# GD32H7xx register map
File version: 1.0
CPU: CM7 r1p2, little endian, MPU, FPU, 4 interrupt priority bits
Registers are 32-bit, read-write, reset 0x0 unless marked. A register's access mark holds for its fields unless they carry their own. Offsets are from the block's base; [hi:lo] are bit positions; {n}, {i} and the like mark numbered series.

## HWSEM — Hardware semaphore
Base 0x58026400
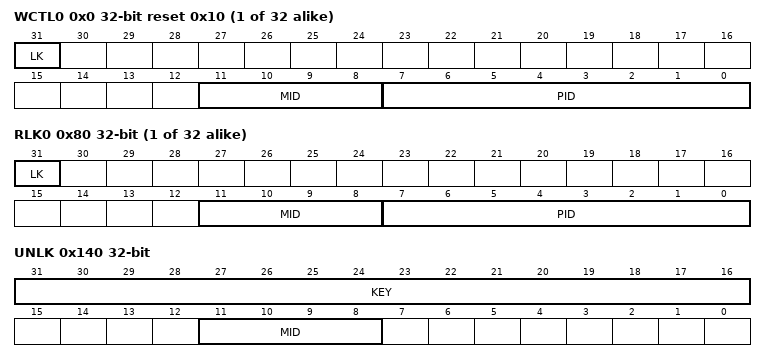
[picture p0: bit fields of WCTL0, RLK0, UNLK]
{0x0+4i} WCTL{i} reset 0x10 (i=0..31) — Write control register {i}
  [31] LK — Lock semaphore by writing
  [11:8] MID — Bus master identification
  [7:0] PID — Process identification
{0x80+4i} RLK{i} ro (i=0..31) — Read lock regist {i}
  [31] LK — Lock semaphore by reading
  [11:8] MID — Bus master identification
  [7:0] PID — Process identification
0x100 INTEN reset 0x4 — Interrupt enable register
  [31:0] SIE — Semaphore interrupt enable bit
0x104 INTC wo — Interrupt flag clear register
  [31:0] SIFC — Semaphore interrupt flag clear bit
0x108 STAT ro — Status register
  [31:0] SF — Semaphore status
0x10C INTF ro — Interrupt flag register
  [31:0] SIF — Semaphore interrupt flag status
0x140 UNLK access per field — Unlock register
  [31:16] KEY rw — Key value
  [11:8] MID wo — Bus master identification to clear
0x144 KEY
  [31:16] KEY — Key for unlocking all semaphores of a bus master

## LPDTS — Lower power digital temperature sensor
Base 0x58006800
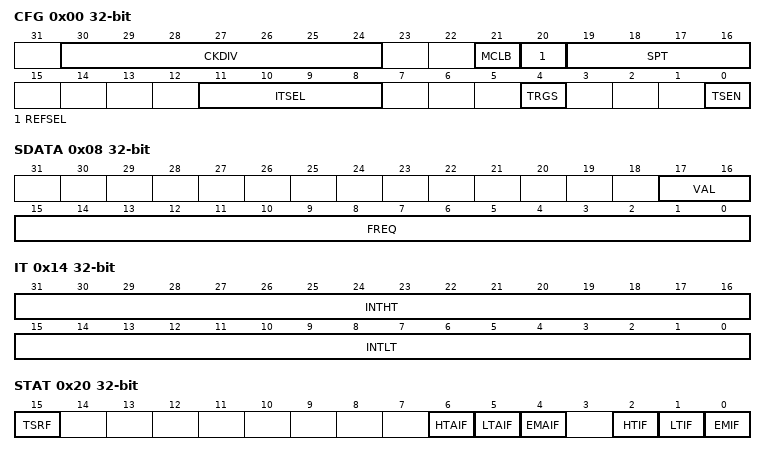
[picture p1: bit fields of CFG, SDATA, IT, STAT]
0x00 CFG — configuration register
  [30:24] CKDIV — High speed clock division
  [21] MCLB — Calibration option for quick measurement
  [20] REFSEL — Reference clock selection
  [19:16] SPT — Sampling time
  [11:8] ITSEL — Input trigger selection
  [4] TRGS — Trigger selection for frequency measurement
  [0] TSEN — Enable temperature sensor
0x08 SDATA ro — sensor T0 data register 1
  [17:16] VAL — Engineering value
  [15:0] FREQ — Frequency value
0x10 RDATA ro — ramp data register
  [15:0] RCVAL — Ramp coefficient
0x14 IT ro — Interrupt threshold register
  [31:16] INTHT — Interrupt high threshold
  [15:0] INTLT — Interrupt low threshold
0x1C DATA ro — Temperature data register
  [15:0] COVAL — Value of the counter output
0x20 STAT ro — Temperature sensor status register
  [15] TSRF — Temperature sensor ready flag
  [6] HTAIF — High threshold asynchronous interrupt flag
  [5] LTAIF — Low threshold asynchronous interrupt flag
  [4] EMAIF — End of measurement asynchronous interrupt flag
  [2] HTIF — High threshold interrupt flag
  [1] LTIF — Low threshold interrupt flag
  [0] EMIF — End of measurement interrupt flag
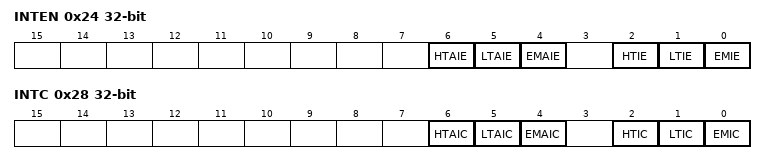
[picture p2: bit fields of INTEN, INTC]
0x24 INTEN — Interrupt enable register
  [6] HTAIE — High threshold asynchronous interrupt enable
  [5] LTAIE — Low threshold asynchronous interrupt enable
  [4] EMAIE — End of measurement asynchronous interrupt enable
  [2] HTIE — High threshold interrupt enable
  [1] LTIE — Low threshold interrupt enable
  [0] EMIE — End of measurement interrupt enable
0x28 INTC — Interrupt clear flag register
  [6] HTAIC — High threshold asynchronous interrupt clear
  [5] LTAIC — Low threshold asynchronous interrupt clear
  [4] EMAIC — End of Measure asynchronous interrupt clear
  [2] HTIC — High threshold interrupt clear
  [1] LTIC — Low threshold interrupt clear
  [0] EMIC — End of measurement interrupt clear
0x2C OP ro — Option register
  [31:0] OP — general purpose option bits

## MDIO — Management data input/output
Base 0x40009400
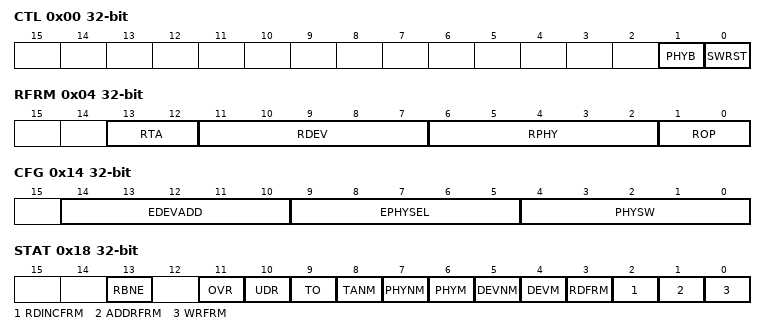
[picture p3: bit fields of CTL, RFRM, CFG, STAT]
0x00 CTL — Control register
  [1] PHYB — MDIO PHY bit length
  [0] SWRST — Software reset
0x04 RFRM — Received frame information register
  [13:12] RTA — Received frame field TA
  [11:7] RDEV — Received frame field DEVADD
  [6:2] RPHY — Received frame field PHYADR
  [1:0] ROP — Received frame field OP
0x08 RDATA ro — Received data register
  [15:0] RDATA — Received frame field DATA
0x0C RADDR ro — Received address register
  [15:0] RADDR — Received frame field ADDRESS
0x10 TDATA ro — Transfer data register
  [15:0] TDATA — Transfer data
0x14 CFG — Configuration register
  [14:10] EDEVADD — Expected DEVADD
  [9:5] EPHYSEL — Selects expected PHYADR
  [4:0] PHYSW — Software provided PHYADR
0x18 STAT ro — Status register
  [13] RBNE — Read data buffer not empty flag
  [11] OVR — Receive overrun flag
  [10] UDR — Transmit underrun flag
  [9] TO — Timeout flag
  [8] TANM — Set at end bit of TA of a write data frame or a write address frame
  [7] PHYNM — Set at end bit of PHYADR if PHYADR nonmatches
  [6] PHYM — Set at end bit of PHYADR if PHYADR matches
  [5] DEVNM — Set at end bit of DEVADD if DEVADD nonmatches
  [4] DEVM — Set at end bit of DEVADD if DEVADD matches
  [3] RDFRM — Set at end bit of a read data frame if DEVADD and PHYADR both match
  [2] RDINCFRM — Set at end bit of a post read increment address frame if DEVADD and PHYADR both match
  [1] ADDRFRM — Set at end bit of a write address frame if DEVADD and PHYADR both match
  [0] WRFRM — Set at end bit of a write data frame if DEVADD and PHYADR both match
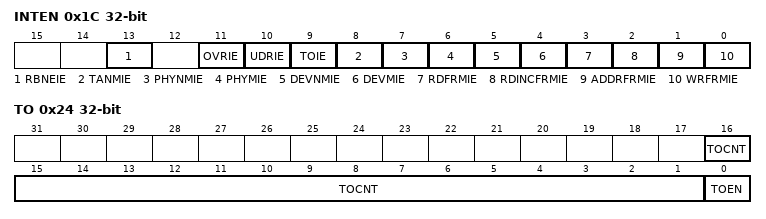
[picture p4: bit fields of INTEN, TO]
0x1C INTEN — Interrupt enable register
  [13] RBNEIE — interrupt is requested when RBDE bit in MDIO_STAT register becomes active
  [11] OVRIE — interrupt is requested when OVR bit in MDIO_STAT register becomes active
  [10] UDRIE — interrupt is requested when UDR bit in MDIO_STAT register becomes active
  [9] TOIE — interrupt is requested when TO bit in MDIO_STAT register becomes active
  [8] TANMIE — interrupt is requested when TANM bit in MDIO_STAT register becomes active
  [7] PHYNMIE — interrupt is requested when PHYNM bit in MDIO_STAT register becomes active
  [6] PHYMIE — interrupt is requested when PHYM bit in MDIO_STAT register becomes active
  [5] DEVNMIE — interrupt is requested when DEVNM bit in MDIO_STAT register becomes active
  [4] DEVMIE — interrupt is requested when DEVM bit in MDIO_STAT register becomes active
  [3] RDFRMIE — interrupt is requested when RDFRM bit in MDIO_STAT register becomes active
  [2] RDINCFRMIE — interrupt is requested when RDINCFRM bit in MDIO_STAT register becomes active
  [1] ADDRFRMIE — interrupt is requested when ADDRFRM bit in MDIO_STAT register becomes active
  [0] WRFRMIE — interrupt is requested when WRFRM bit in MDIO_STAT register becomes active
0x20 PIN ro — pin value register
  [4:0] PHYPIN — Pin value read from hardware PRTADR[4:0] pins
0x24 TO ro — Timeout register
  [16:1] TOCNT — MDIO time out
  [0] TOEN — Timeout enable
